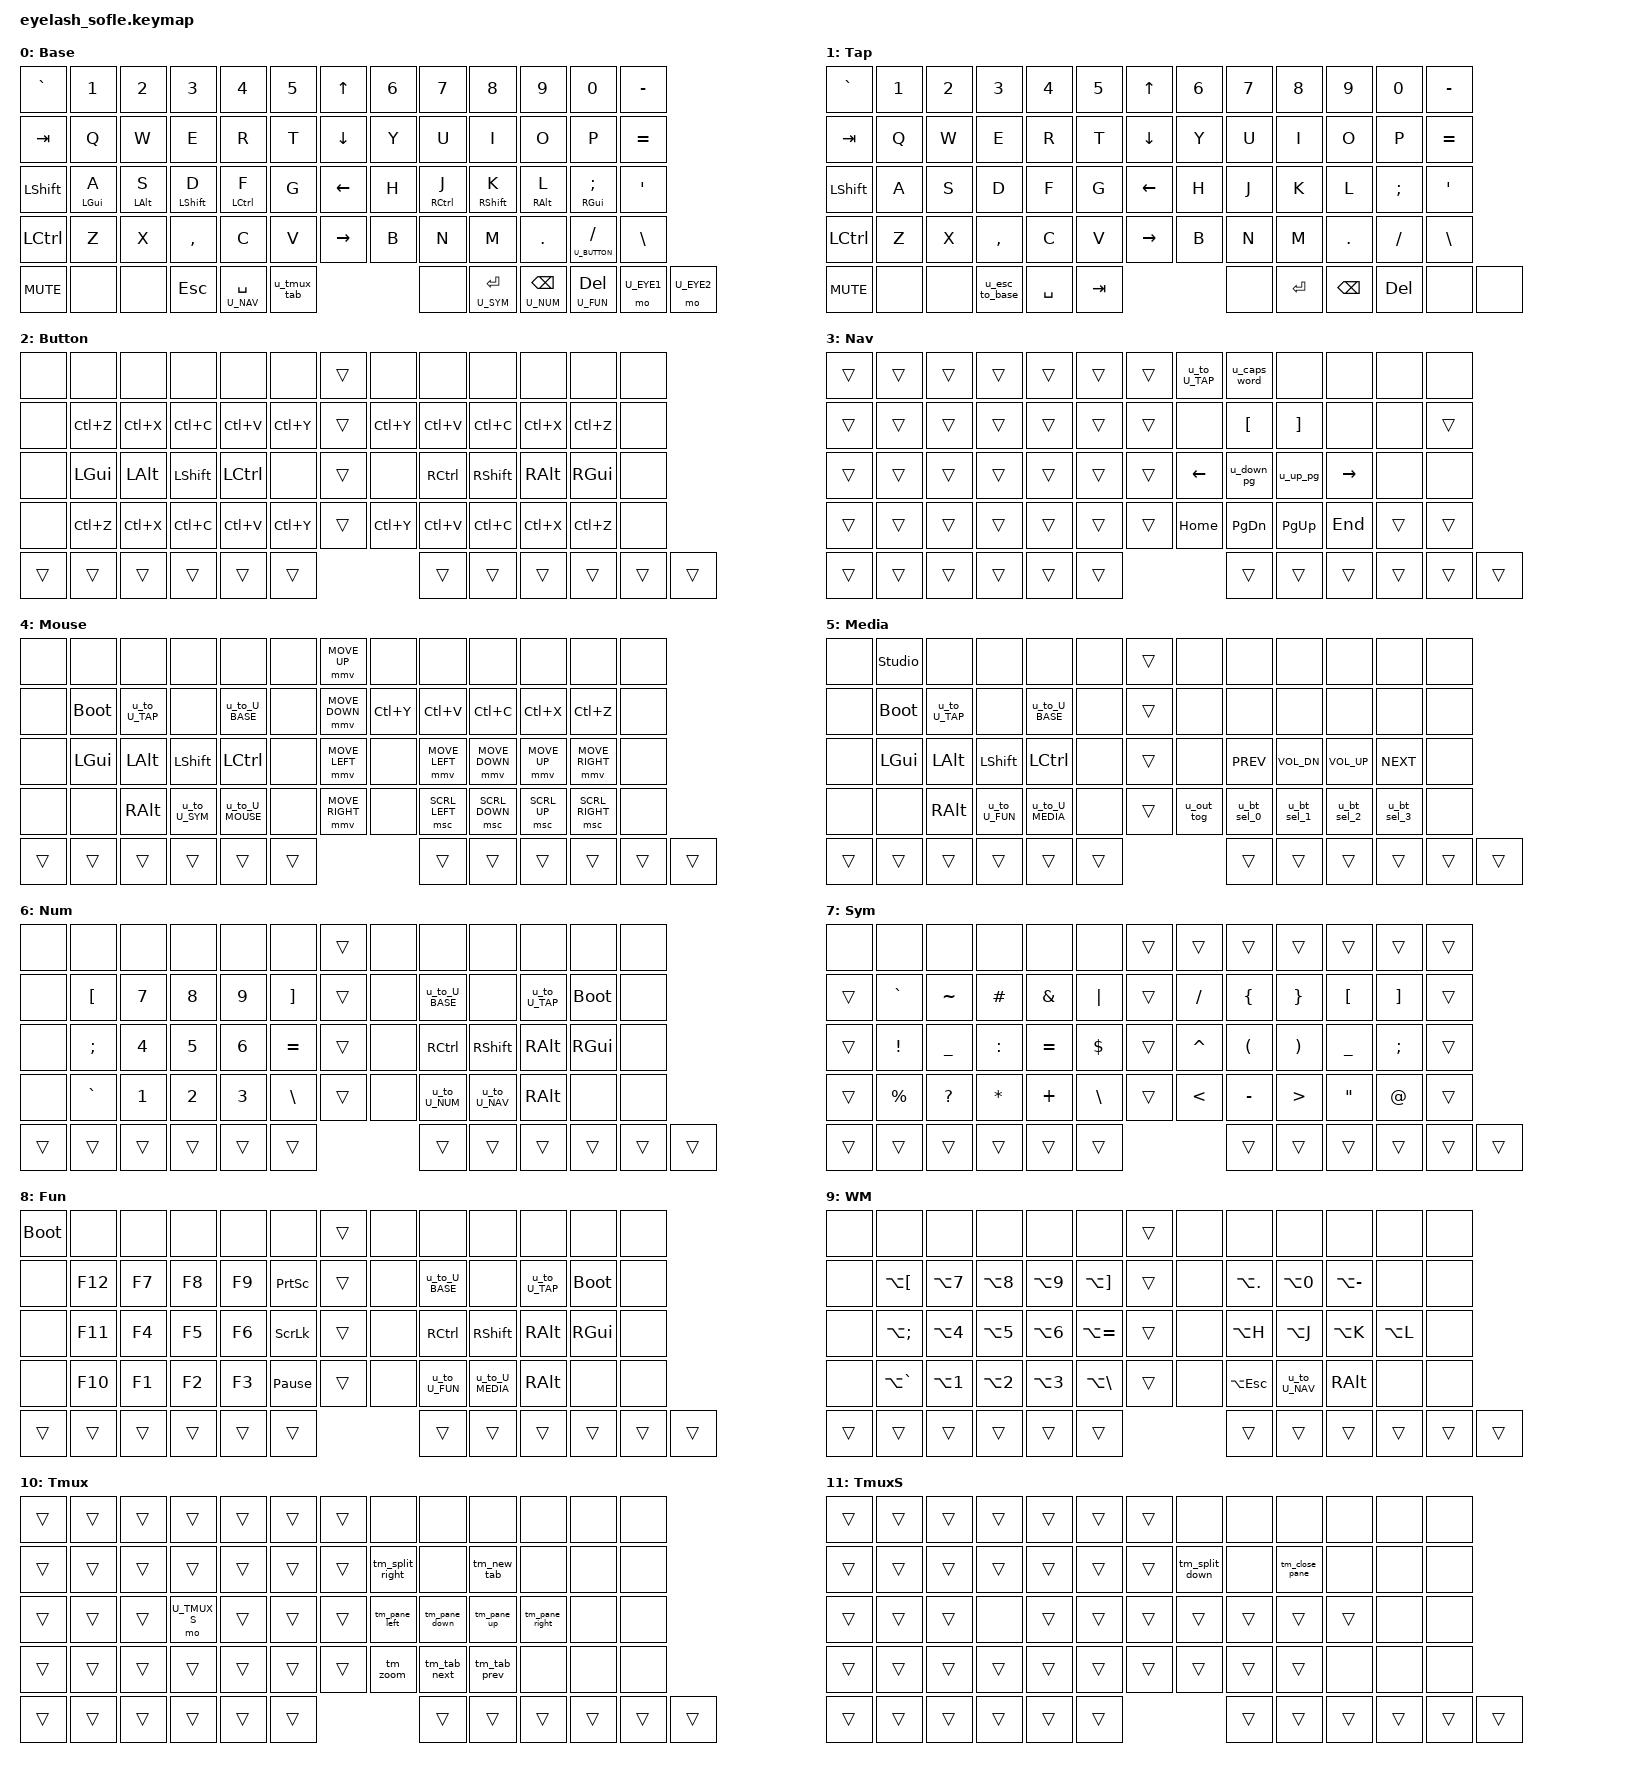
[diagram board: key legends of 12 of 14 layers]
/*
 * Eyelash Sofle — QWERTY, GASC home-row mods.
 *
 * 64 matrix positions:
 *   Rows 0–3: 6 left + hat + 6 right = 13
 *   Row 4:    encoder, 5 left thumbs, hat click, 5 right thumbs = 12
 *
 * Thumbs, left outer→inner, then right inner→outer:
 *   spare, spare, Esc, Space/Nav, Tab/Tmux
 *   Enter/Sym, Backspace/Num, Del/Fun, Eyelash 1, Eyelash 2
 *
 * TMUX layer (hold Tab): every action is the Ctrl-b prefix plus a key —
 * H/J/K/L panes (prefix+arrows), Y split right, I new tab, B zoom, N/M next/previous tab.
 * Hold home-row D while on TMUX, or hold D then Tab, for TMUX_S
 * (Y split down, I close pane). Base D+Tab tap remains Shift+Tab.
 *
 * Clipboard macros send Ctrl, matching the previous Lily58 keymap.
 */

#include <behaviors.dtsi>
#include <behaviors/mouse_keys.dtsi>
#include <dt-bindings/zmk/keys.h>
#include <dt-bindings/zmk/bt.h>
#include <dt-bindings/zmk/outputs.h>
#include <dt-bindings/zmk/pointing.h>
#include <dt-bindings/zmk/rgb.h>

/* ── Layer indices ─────────────────────────────────────────────── */
#define U_BASE   0
#define U_TAP    1
#define U_BUTTON 2
#define U_NAV    3
#define U_MOUSE  4
#define U_MEDIA  5
#define U_NUM    6
#define U_SYM    7
#define U_FUN    8
#define U_WM     9
#define U_TMUX   10
#define U_TMUX_S 11
#define U_EYE1   12
#define U_EYE2   13

/* ── Mouse defaults ────────────────────────────────────────────── */
#define ZMK_POINTING_DEFAULT_MOVE_VAL 1250
#define ZMK_POINTING_DEFAULT_SCRL_VAL 100

/* ── Clipboard (Windows) ───────────────────────────────────────── */
#define U_RDO &kp LC(Y)
#define U_PST &kp LC(V)
#define U_CPY &kp LC(C)
#define U_CUT &kp LC(X)
#define U_UND &kp LC(Z)

/* ── Mouse key aliases ─────────────────────────────────────────── */
#define U_BTN1 &mkp MB1
#define U_BTN2 &mkp MB2
#define U_BTN3 &mkp MB3
#define U_MS_D &mmv MOVE_DOWN
#define U_MS_L &mmv MOVE_LEFT
#define U_MS_R &mmv MOVE_RIGHT
#define U_MS_U &mmv MOVE_UP
#define U_WH_D &msc SCRL_DOWN
#define U_WH_L &msc SCRL_LEFT
#define U_WH_R &msc SCRL_RIGHT
#define U_WH_U &msc SCRL_UP

/* ── Mouse movement tuning ─────────────────────────────────────── */
&mmv {
    acceleration-exponent = <1>;
    time-to-max-speed-ms = <1500>;
    delay-ms = <0>;
};

/* ── Macros ────────────────────────────────────────────────────── */
/ {
    scroll_enc: scroll_enc {
        compatible = "zmk,behavior-sensor-rotate";
        #sensor-binding-cells = <0>;
        bindings = <&msc SCRL_UP>, <&msc SCRL_DOWN>;
    };

    macros {
        u_macro_u_bt_sel_0: u_macro_u_bt_sel_0 {
            compatible = "zmk,behavior-macro";
            #binding-cells = <0>;
            wait-ms = <0>;
            bindings = <&bt BT_SEL 0 &bt BT_CLR>;
        };
        u_macro_u_bt_sel_1: u_macro_u_bt_sel_1 {
            compatible = "zmk,behavior-macro";
            #binding-cells = <0>;
            wait-ms = <0>;
            bindings = <&bt BT_SEL 1 &bt BT_CLR>;
        };
        u_macro_u_bt_sel_2: u_macro_u_bt_sel_2 {
            compatible = "zmk,behavior-macro";
            #binding-cells = <0>;
            wait-ms = <0>;
            bindings = <&bt BT_SEL 2 &bt BT_CLR>;
        };
        u_macro_u_bt_sel_3: u_macro_u_bt_sel_3 {
            compatible = "zmk,behavior-macro";
            #binding-cells = <0>;
            wait-ms = <0>;
            bindings = <&bt BT_SEL 3 &bt BT_CLR>;
        };
        u_macro_u_bt_sel_4: u_macro_u_bt_sel_4 {
            compatible = "zmk,behavior-macro";
            #binding-cells = <0>;
            wait-ms = <0>;
            bindings = <&bt BT_SEL 4 &bt BT_CLR>;
        };

        /* TMUX layer — tmux actions. Every binding is the Ctrl-b prefix plus
           one key, sent as two separate taps: tmux wants the prefix RELEASED
           before the action key, so these must never be a three-key chord.
           40/40 is a starting point — if the prefix is swallowed, raise it
           (80–120). */
        /* Pane focus: prefix+arrows (LEFT/DOWN/UP/RIGHT). Physical H/J/K/L. */
        tm_pane_left: tm_pane_left {
            compatible = "zmk,behavior-macro";
            #binding-cells = <0>;
            wait-ms = <40>;
            tap-ms = <40>;
            bindings = <&kp LC(B) &kp LEFT>;
        };
        tm_pane_down: tm_pane_down {
            compatible = "zmk,behavior-macro";
            #binding-cells = <0>;
            wait-ms = <40>;
            tap-ms = <40>;
            bindings = <&kp LC(B) &kp DOWN>;
        };
        tm_pane_up: tm_pane_up {
            compatible = "zmk,behavior-macro";
            #binding-cells = <0>;
            wait-ms = <40>;
            tap-ms = <40>;
            bindings = <&kp LC(B) &kp UP>;
        };
        tm_pane_right: tm_pane_right {
            compatible = "zmk,behavior-macro";
            #binding-cells = <0>;
            wait-ms = <40>;
            tap-ms = <40>;
            bindings = <&kp LC(B) &kp RIGHT>;
        };
        /* Split right: prefix+% (tmux default; % is Shift+5, LS(N5)). */
        tm_split_right: tm_split_right {
            compatible = "zmk,behavior-macro";
            #binding-cells = <0>;
            wait-ms = <40>;
            tap-ms = <40>;
            bindings = <&kp LC(B) &kp LS(N5)>;
        };
        /* Split down: prefix+" (tmux default; " is Shift+', LS(SQT)). LS is pressed by the macro itself. */
        tm_split_down: tm_split_down {
            compatible = "zmk,behavior-macro";
            #binding-cells = <0>;
            wait-ms = <40>;
            tap-ms = <40>;
            bindings = <&kp LC(B) &kp LS(SQT)>;
        };
        /* New tab: prefix+c. */
        tm_new_tab: tm_new_tab {
            compatible = "zmk,behavior-macro";
            #binding-cells = <0>;
            wait-ms = <40>;
            tap-ms = <40>;
            bindings = <&kp LC(B) &kp C>;
        };
        /* Close pane: prefix+x. */
        tm_close_pane: tm_close_pane {
            compatible = "zmk,behavior-macro";
            #binding-cells = <0>;
            wait-ms = <40>;
            tap-ms = <40>;
            bindings = <&kp LC(B) &kp X>;
        };
        /* Zoom pane: prefix+z. */
        tm_zoom: tm_zoom {
            compatible = "zmk,behavior-macro";
            #binding-cells = <0>;
            wait-ms = <40>;
            tap-ms = <40>;
            bindings = <&kp LC(B) &kp Z>;
        };
        /* Next tab: prefix+n. */
        tm_tab_next: tm_tab_next {
            compatible = "zmk,behavior-macro";
            #binding-cells = <0>;
            wait-ms = <40>;
            tap-ms = <40>;
            bindings = <&kp LC(B) &kp N>;
        };
        /* Previous tab: prefix+p. */
        tm_tab_prev: tm_tab_prev {
            compatible = "zmk,behavior-macro";
            #binding-cells = <0>;
            wait-ms = <40>;
            tap-ms = <40>;
            bindings = <&kp LC(B) &kp P>;
        };
    };
};

/* ── Behaviors ─────────────────────────────────────────────────── */
/ {
    behaviors {
        /* Home-row mods. Balanced: hold if other key pressed+released while held; alone timeout still hold. */
        u_mt: u_mt {
            compatible = "zmk,behavior-hold-tap";
            #binding-cells = <2>;
            tapping-term-ms = <250>;
            require-prior-idle-ms = <120>;
            flavor = "balanced";
            bindings = <&kp>, <&kp>;
        };

        /* Hold = momentary layer, tap = key. */
        u_lt: u_lt {
            compatible = "zmk,behavior-hold-tap";
            #binding-cells = <2>;
            tapping-term-ms = <250>;
            require-prior-idle-ms = <120>;
            flavor = "tap-preferred";
            bindings = <&mo>, <&kp>;
        };

        /* Tab/TMUX entry. Unshifted: hold TMUX, tap Tab. With Shift already
           held: hold TMUX_S (Shift masked for the hold), tap Shift+Tab via
           LS(TAB). No keep-mods — masking is required to stop D-then-Tab-hold
           from leaking LSHFT into Ctrl-b macros. */
        u_tmux_tab: u_tmux_tab {
            compatible = "zmk,behavior-mod-morph";
            #binding-cells = <0>;
            bindings = <&u_lt U_TMUX TAB>, <&u_lt U_TMUX_S LS(TAB)>;
            mods = <(MOD_LSFT|MOD_RSFT)>;
        };

        u_bt_sel_0: u_bt_sel_0 {
            compatible = "zmk,behavior-mod-morph";
            #binding-cells = <0>;
            bindings = <&bt BT_SEL 0>, <&u_macro_u_bt_sel_0>;
            mods = <(MOD_LSFT|MOD_RSFT)>;
        };
        u_bt_sel_1: u_bt_sel_1 {
            compatible = "zmk,behavior-mod-morph";
            #binding-cells = <0>;
            bindings = <&bt BT_SEL 1>, <&u_macro_u_bt_sel_1>;
            mods = <(MOD_LSFT|MOD_RSFT)>;
        };
        u_bt_sel_2: u_bt_sel_2 {
            compatible = "zmk,behavior-mod-morph";
            #binding-cells = <0>;
            bindings = <&bt BT_SEL 2>, <&u_macro_u_bt_sel_2>;
            mods = <(MOD_LSFT|MOD_RSFT)>;
        };
        u_bt_sel_3: u_bt_sel_3 {
            compatible = "zmk,behavior-mod-morph";
            #binding-cells = <0>;
            bindings = <&bt BT_SEL 3>, <&u_macro_u_bt_sel_3>;
            mods = <(MOD_LSFT|MOD_RSFT)>;
        };
        u_bt_sel_4: u_bt_sel_4 {
            compatible = "zmk,behavior-mod-morph";
            #binding-cells = <0>;
            bindings = <&bt BT_SEL 4>, <&u_macro_u_bt_sel_4>;
            mods = <(MOD_LSFT|MOD_RSFT)>;
        };

        u_out_tog: u_out_tog {
            compatible = "zmk,behavior-mod-morph";
            #binding-cells = <0>;
            bindings = <&out OUT_TOG>, <&out OUT_USB>;
            mods = <(MOD_LSFT|MOD_RSFT)>;
        };

        u_caps_word: u_caps_word {
            compatible = "zmk,behavior-mod-morph";
            #binding-cells = <0>;
            bindings = <&caps_word>, <&kp CAPS>;
            mods = <(MOD_LSFT|MOD_RSFT)>;
        };

        /* Up, or Page Up while Alt is held (Alt is not sent). */
        u_up_pg: u_up_pg {
            compatible = "zmk,behavior-mod-morph";
            #binding-cells = <0>;
            bindings = <&kp UP>, <&kp PG_UP>;
            mods = <(MOD_LALT|MOD_RALT)>;
        };
        /* Down, or Page Down while Alt is held (Alt is not sent). */
        u_down_pg: u_down_pg {
            compatible = "zmk,behavior-mod-morph";
            #binding-cells = <0>;
            bindings = <&kp DOWN>, <&kp PG_DN>;
            mods = <(MOD_LALT|MOD_RALT)>;
        };

        /* Double-tap guards: require a second tap to lock a layer. */
        u_to_U_BASE: u_to_U_BASE {
            compatible = "zmk,behavior-tap-dance";
            #binding-cells = <0>;
            tapping-term-ms = <200>;
            bindings = <&none>, <&to U_BASE>;
        };
        u_to_U_TAP: u_to_U_TAP {
            compatible = "zmk,behavior-tap-dance";
            #binding-cells = <0>;
            tapping-term-ms = <200>;
            bindings = <&none>, <&to U_TAP>;
        };
        u_to_U_BUTTON: u_to_U_BUTTON {
            compatible = "zmk,behavior-tap-dance";
            #binding-cells = <0>;
            tapping-term-ms = <200>;
            bindings = <&none>, <&to U_BUTTON>;
        };
        u_to_U_NAV: u_to_U_NAV {
            compatible = "zmk,behavior-tap-dance";
            #binding-cells = <0>;
            tapping-term-ms = <200>;
            bindings = <&none>, <&to U_NAV>;
        };
        u_to_U_MOUSE: u_to_U_MOUSE {
            compatible = "zmk,behavior-tap-dance";
            #binding-cells = <0>;
            tapping-term-ms = <200>;
            bindings = <&none>, <&to U_MOUSE>;
        };
        u_to_U_MEDIA: u_to_U_MEDIA {
            compatible = "zmk,behavior-tap-dance";
            #binding-cells = <0>;
            tapping-term-ms = <200>;
            bindings = <&none>, <&to U_MEDIA>;
        };
        u_to_U_NUM: u_to_U_NUM {
            compatible = "zmk,behavior-tap-dance";
            #binding-cells = <0>;
            tapping-term-ms = <200>;
            bindings = <&none>, <&to U_NUM>;
        };
        u_to_U_SYM: u_to_U_SYM {
            compatible = "zmk,behavior-tap-dance";
            #binding-cells = <0>;
            tapping-term-ms = <200>;
            bindings = <&none>, <&to U_SYM>;
        };
        u_to_U_FUN: u_to_U_FUN {
            compatible = "zmk,behavior-tap-dance";
            #binding-cells = <0>;
            tapping-term-ms = <200>;
            bindings = <&none>, <&to U_FUN>;
        };
        u_to_U_WM: u_to_U_WM {
            compatible = "zmk,behavior-tap-dance";
            #binding-cells = <0>;
            tapping-term-ms = <200>;
            bindings = <&none>, <&to U_WM>;
        };

        /* Esc tap, double-tap leaves the Tap layer. */
        u_esc_to_base: u_esc_to_base {
            compatible = "zmk,behavior-tap-dance";
            #binding-cells = <0>;
            tapping-term-ms = <200>;
            bindings = <&kp ESC>, <&to U_BASE>;
        };
    };
};

/ {
    keymap {
        compatible = "zmk,keymap";

        /* 0: BASE — QWERTY, GASC on the home row. */
        BASE {
            display-name = "Base";
            bindings = <
&kp GRAVE  &kp N1  &kp N2  &kp N3  &kp N4  &kp N5   &kp UP    &kp N6  &kp N7  &kp N8  &kp N9  &kp N0    &kp MINUS
&kp TAB    &kp Q   &kp W   &kp E   &kp R   &kp T    &kp DOWN  &kp Y   &kp U   &kp I   &kp O   &kp P     &kp EQUAL
&kp LSHFT  &u_mt LGUI A  &u_mt LALT S  &u_mt LSHFT D  &u_mt LCTRL F  &kp G   &kp LEFT  &kp H  &u_mt RCTRL J  &u_mt RSHFT K  &u_mt RALT L  &u_mt RGUI SEMI  &kp SQT
&kp LCTRL  &kp Z  &kp X  &kp COMMA  &kp C  &kp V   &kp RIGHT  &kp B  &kp N  &kp M  &kp DOT  &u_lt U_BUTTON SLASH  &kp BSLH
&kp C_MUTE &none &none &kp ESC &u_lt U_NAV SPACE &u_tmux_tab  &none  &u_lt U_SYM RET &u_lt U_NUM BSPC &u_lt U_FUN DEL &mo U_EYE1 &mo U_EYE2
            >;
            sensor-bindings = <&inc_dec_kp C_VOL_UP C_VOL_DN>;
        };

        /* 1: TAP — same QWERTY letters, no hold-taps. Double-tap Esc returns to Base. */
        TAP {
            display-name = "Tap";
            bindings = <
&kp GRAVE &kp N1 &kp N2 &kp N3 &kp N4 &kp N5  &kp UP    &kp N6 &kp N7 &kp N8 &kp N9 &kp N0 &kp MINUS
&kp TAB   &kp Q  &kp W  &kp E  &kp R  &kp T   &kp DOWN  &kp Y  &kp U  &kp I  &kp O  &kp P  &kp EQUAL
&kp LSHFT &kp A  &kp S  &kp D  &kp F  &kp G   &kp LEFT  &kp H  &kp J  &kp K  &kp L  &kp SEMI &kp SQT
&kp LCTRL &kp Z &kp X &kp COMMA &kp C &kp V  &kp RIGHT &kp B &kp N &kp M &kp DOT &kp SLASH &kp BSLH
&kp C_MUTE &none &none &u_esc_to_base &kp SPACE &kp TAB  &none  &kp RET &kp BSPC &kp DEL &none &none
            >;
            sensor-bindings = <&inc_dec_kp C_VOL_UP C_VOL_DN>;
        };

        /* 2: BUTTON — clipboard and mouse buttons. Thumbs fall through to Base. */
        BUTTON {
            display-name = "Button";
            bindings = <
&none &none &none &none &none &none  &trans  &none &none &none &none &none &none
&none U_UND U_CUT U_CPY U_PST U_RDO  &trans  U_RDO U_PST U_CPY U_CUT U_UND &none
&none &kp LGUI &kp LALT &kp LSHFT &kp LCTRL &none  &trans  &none &kp RCTRL &kp RSHFT &kp RALT &kp RGUI &none
&none U_UND U_CUT U_CPY U_PST U_RDO  &trans  U_RDO U_PST U_CPY U_CUT U_UND &none
&trans &trans &trans &trans &trans &trans  &trans  &trans &trans &trans &trans &trans
            >;
            sensor-bindings = <&inc_dec_kp C_VOL_UP C_VOL_DN>;
        };

        /* 3: NAV — hold Space. */
        NAV {
            display-name = "Nav";
            bindings = <
&trans &trans &trans &trans &trans &trans  &trans  &u_to_U_TAP &u_caps_word &none &none &none &none
&trans &trans &trans &trans &trans &trans  &trans  &none &kp LBKT &kp RBKT &none &none &trans
&trans &trans &trans &trans &trans &trans  &trans  &kp LEFT &u_down_pg &u_up_pg &kp RIGHT &none &none
&trans &trans &trans &trans &trans &trans  &trans  &kp HOME &kp PG_DN &kp PG_UP &kp END &trans &trans
&trans &trans &trans &trans &trans &trans  &trans  &trans &trans &trans &trans &trans
            >;
            sensor-bindings = <&inc_dec_kp C_VOL_UP C_VOL_DN>;
        };

        /* 4: MOUSE */
        MOUSE {
            display-name = "Mouse";
            bindings = <
&none &none &none &none &none &none  &mmv MOVE_UP  &none &none &none &none &none &none
&none &bootloader &u_to_U_TAP &none &u_to_U_BASE &none  &mmv MOVE_DOWN  U_RDO U_PST U_CPY U_CUT U_UND &none
&none &kp LGUI &kp LALT &kp LSHFT &kp LCTRL &none  &mmv MOVE_LEFT  &none U_MS_L U_MS_D U_MS_U U_MS_R &none
&none &none &kp RALT &u_to_U_SYM &u_to_U_MOUSE &none  &mmv MOVE_RIGHT  &none U_WH_L U_WH_D U_WH_U U_WH_R &none
&trans &trans &trans &trans &trans &trans  &trans  &trans &trans &trans &trans &trans
            >;
            sensor-bindings = <&scroll_enc>;
        };

        /* 5: MEDIA — Bluetooth, output, studio unlock. */
        MEDIA {
            display-name = "Media";
            bindings = <
&none &studio_unlock &none &none &none &none  &trans  &none &none &none &none &none &none
&none &bootloader &u_to_U_TAP &none &u_to_U_BASE &none  &trans  &none &none &none &none &none &none
&none &kp LGUI &kp LALT &kp LSHFT &kp LCTRL &none  &trans  &none &kp C_PREV &kp C_VOL_DN &kp C_VOL_UP &kp C_NEXT &none
&none &none &kp RALT &u_to_U_FUN &u_to_U_MEDIA &none  &trans  &u_out_tog &u_bt_sel_0 &u_bt_sel_1 &u_bt_sel_2 &u_bt_sel_3 &none
&trans &trans &trans &trans &trans &trans  &trans  &trans &trans &trans &trans &trans
            >;
            sensor-bindings = <&inc_dec_kp C_VOL_UP C_VOL_DN>;
        };

        /* 6: NUM */
        NUM {
            display-name = "Num";
            bindings = <
&none &none &none &none &none &none  &trans  &none &none &none &none &none &none
&none &kp LBKT &kp N7 &kp N8 &kp N9 &kp RBKT  &trans  &none &u_to_U_BASE &none &u_to_U_TAP &bootloader &none
&none &kp SEMI &kp N4 &kp N5 &kp N6 &kp EQUAL  &trans  &none &kp RCTRL &kp RSHFT &kp RALT &kp RGUI &none
&none &kp GRAVE &kp N1 &kp N2 &kp N3 &kp BSLH  &trans  &none &u_to_U_NUM &u_to_U_NAV &kp RALT &none &none
&trans &trans &trans &trans &trans &trans  &trans  &trans &trans &trans &trans &trans
            >;
            sensor-bindings = <&inc_dec_kp C_VOL_UP C_VOL_DN>;
        };

        /* 7: SYM — bilateral 3x5 freeze (hold Enter) */
        SYM {
            display-name = "Sym";
            bindings = <
&none &none &none &none &none &none  &trans  &trans &trans &trans &trans &trans &trans
&trans &kp GRAVE &kp TILDE &kp HASH &kp AMPS &kp PIPE  &trans  &kp SLASH &kp LBRC &kp RBRC &kp LBKT &kp RBKT &trans
&trans &kp EXCL &kp UNDER &kp COLON &kp EQUAL &kp DLLR  &trans  &kp CARET &kp LPAR &kp RPAR &kp UNDER &kp SEMI &trans
&trans &kp PRCNT &kp QMARK &kp ASTRK &kp PLUS &kp BSLH  &trans  &kp LT &kp MINUS &kp GT &kp DQT &kp AT &trans
&trans &trans &trans &trans &trans &trans  &trans  &trans &trans &trans &trans &trans
            >;
            sensor-bindings = <&inc_dec_kp C_VOL_UP C_VOL_DN>;
        };

        /* 8: FUN — the previous function layer, held on Delete. */
        FUN {
            display-name = "Fun";
            bindings = <
&bootloader &none &none &none &none &none  &trans  &none &none &none &none &none &none
&none &kp F12 &kp F7 &kp F8 &kp F9 &kp PSCRN  &trans  &none &u_to_U_BASE &none &u_to_U_TAP &bootloader &none
&none &kp F11 &kp F4 &kp F5 &kp F6 &kp SLCK  &trans  &none &kp RCTRL &kp RSHFT &kp RALT &kp RGUI &none
&none &kp F10 &kp F1 &kp F2 &kp F3 &kp PAUSE_BREAK  &trans  &none &u_to_U_FUN &u_to_U_MEDIA &kp RALT &none &none
&trans &trans &trans &trans &trans &trans  &trans  &trans &trans &trans &trans &trans
            >;
            sensor-bindings = <&inc_dec_kp C_VOL_UP C_VOL_DN>;
        };

        /* 9: WM — AeroSpace. No key opens this layer yet. */
        WM {
            display-name = "WM";
            bindings = <
&none &none &none &none &none &none  &trans  &none &none &none &none &none &none
&none &kp LA(LBKT) &kp LA(N7) &kp LA(N8) &kp LA(N9) &kp LA(RBKT)  &trans  &none &kp LA(DOT) &kp LA(N0) &kp LA(MINUS) &none &none
&none &kp LA(SEMI) &kp LA(N4) &kp LA(N5) &kp LA(N6) &kp LA(EQUAL)  &trans  &none &kp LA(H) &kp LA(J) &kp LA(K) &kp LA(L) &none
&none &kp LA(GRAVE) &kp LA(N1) &kp LA(N2) &kp LA(N3) &kp LA(BSLH)  &trans  &none &kp LA(ESC) &u_to_U_NAV &kp RALT &none &none
&trans &trans &trans &trans &trans &trans  &trans  &trans &trans &trans &trans &trans
            >;
            sensor-bindings = <&inc_dec_kp C_VOL_UP C_VOL_DN>;
        };

        /* 10: TMUX — tmux actions, each Ctrl-b prefix + key. Hold Tab. Left hand
           falls through, so typing continues. H/J/K/L send prefix+arrows for pane
           focus, Y splits right, I opens a tab, B zooms, N/M go to next/previous tab.
           Hold home-row D for TMUX_S; D then hold Tab also enters TMUX_S. Everything else is none. */
        TMUX {
            display-name = "Tmux";
            bindings = <
&trans &trans &trans &trans &trans &trans  &trans  &none &none &none &none &none &none
&trans &trans &trans &trans &trans &trans  &trans  &tm_split_right &none &tm_new_tab &none &none &none
&trans &trans &trans &mo U_TMUX_S &trans &trans  &trans  &tm_pane_left &tm_pane_down &tm_pane_up &tm_pane_right &none &none
&trans &trans &trans &trans &trans &trans  &trans  &tm_zoom &tm_tab_next &tm_tab_prev &none &none &none
&trans &trans &trans &trans &trans &trans  &trans  &trans &trans &trans &trans &trans
            >;
            sensor-bindings = <&inc_dec_kp C_VOL_UP C_VOL_DN>;
        };

        /* 11: TMUX_S — from TMUX via home-row D, or D-then-Tab hold; Y split down, I close pane. */
        TMUX_S {
            display-name = "TmuxS";
            bindings = <
&trans &trans &trans &trans &trans &trans  &trans  &none &none &none &none &none &none
&trans &trans &trans &trans &trans &trans  &trans  &tm_split_down &none &tm_close_pane &none &none &none
&trans &trans &trans &none &trans &trans  &trans  &trans &trans &trans &trans &none &none
&trans &trans &trans &trans &trans &trans  &trans  &trans &trans &trans &none &none &none
&trans &trans &trans &trans &trans &trans  &trans  &trans &trans &trans &trans &trans
            >;
            sensor-bindings = <&inc_dec_kp C_VOL_UP C_VOL_DN>;
        };

        /* 12: stock Eyelash lower layer. Outer right thumb. */
        EYE1 {
            display-name = "Eye1";
            bindings = <
&kp GRAVE  &kp F1     &kp F2          &kp F3           &kp F4           &kp F5           &mmv MOVE_UP     &kp F6           &kp F7           &kp F8      &kp F9     &kp F10           &trans
&trans     &kp GRAVE  &mkp LCLK       &mkp MCLK        &mkp RCLK        &mkp MB4         &mmv MOVE_DOWN   &kp PG_UP        &kp END          &kp UP      &kp HOME   &kp MINUS         &kp EQUAL
&trans     &kp TILDE  &trans          &trans           &trans           &mkp MB5         &mmv MOVE_LEFT   &kp PG_DN        &kp LEFT         &kp DOWN    &kp RIGHT  &kp LEFT_BRACKET  &kp RIGHT_BRACKET
&trans     &rgb_ug RGB_OFF &rgb_ug RGB_ON &rgb_ug RGB_EFF &rgb_ug RGB_EFR &rgb_ug RGB_SPI &mmv MOVE_RIGHT &rgb_ug RGB_BRI &rgb_ug RGB_BRD &kp INSERT &kp F11 &kp F12 &trans
&kp C_MUTE &trans &trans &trans &trans &trans  &mkp LCLK  &trans &trans &trans &trans &trans
            >;
            sensor-bindings = <&inc_dec_kp C_VOL_UP C_VOL_DN>;
        };

        /* 13: stock Eyelash adjust layer. Outermost right thumb. */
        EYE2 {
            display-name = "Eye2";
            bindings = <
&kp TILDE &bt BT_SEL 0 &bt BT_SEL 1 &bt BT_SEL 2 &bt BT_SEL 3 &bt BT_SEL 4  &mmv MOVE_UP    &kp F6 &kp F7 &kp F8  &kp F9  &kp F10  &trans
&trans    &bt BT_CLR   &bt BT_CLR_ALL &trans     &trans       &trans        &mmv MOVE_DOWN  &trans &trans &kp F11 &kp F12 &kp UNDER &kp PLUS
&trans    &out OUT_USB &out OUT_BLE   &trans     &trans       &trans        &mmv MOVE_LEFT  &trans &trans &trans  &trans  &kp LBRC &kp RBRC
&trans    &sys_reset   &trans         &bootloader &trans      &trans        &mmv MOVE_RIGHT &trans &trans &sys_reset &soft_off &bootloader &trans
&trans &trans &trans &trans &trans &trans  &mkp LCLK  &trans &trans &trans &trans &trans
            >;
            sensor-bindings = <&inc_dec_kp C_VOL_UP C_VOL_DN>;
        };
    };
};
